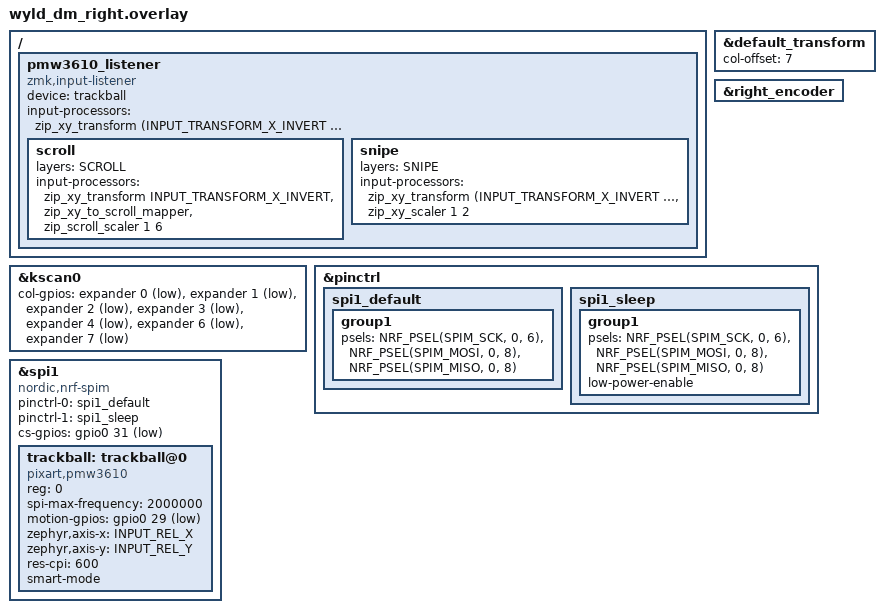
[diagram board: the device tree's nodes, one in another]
// wyld_dm_right.overlay

#define SCROLL 10
#define SNIPE  11

#include "wyld_dm.dtsi"
#include <dt-bindings/led/led.h>
#include <dt-bindings/input/input-event-codes.h>
#include <dt-bindings/zmk/input_transform.h>
#include <input/processors.dtsi>

&default_transform {
    col-offset = <7>;
};


///  NANO V2 PINS

&kscan0 {
    col-gpios
	= <&expander 0 (GPIO_ACTIVE_LOW | GPIO_PULL_UP)>
	, <&expander 1 (GPIO_ACTIVE_LOW | GPIO_PULL_UP)>
	, <&expander 2 (GPIO_ACTIVE_LOW | GPIO_PULL_UP)>
	, <&expander 3 (GPIO_ACTIVE_LOW | GPIO_PULL_UP)>
	, <&expander 4 (GPIO_ACTIVE_LOW | GPIO_PULL_UP)>
	, <&expander 6 (GPIO_ACTIVE_LOW | GPIO_PULL_UP)>
	, <&expander 7 (GPIO_ACTIVE_LOW | GPIO_PULL_UP)>

	;
};


&right_encoder {
	status = "okay";
};

&pinctrl {
    spi1_default: spi1_default {
        group1 {
            psels = <NRF_PSEL(SPIM_SCK, 0, 6)>,
                <NRF_PSEL(SPIM_MOSI, 0, 8)>,
                <NRF_PSEL(SPIM_MISO, 0, 8)>;
        };
    };
    spi1_sleep: spi1_sleep {
        group1 {
            psels = <NRF_PSEL(SPIM_SCK, 0, 6)>,
                <NRF_PSEL(SPIM_MOSI, 0, 8)>,
                <NRF_PSEL(SPIM_MISO, 0, 8)>;
            low-power-enable;
        };
    };
};

&spi1 {
  compatible = "nordic,nrf-spim";
  status = "okay";

  pinctrl-0 = <&spi1_default>;
  pinctrl-1 = <&spi1_sleep>;
  pinctrl-names = "default", "sleep";
  cs-gpios = <&gpio0 31 GPIO_ACTIVE_LOW>;
  trackball: trackball@0 {
      status = "okay";
      compatible = "pixart,pmw3610";
      reg = <0>;
      spi-max-frequency = <2000000>;
      motion-gpios = <&gpio0 29 (GPIO_ACTIVE_LOW | GPIO_PULL_UP)>;
      zephyr,axis-x = <INPUT_REL_X>;
      zephyr,axis-y = <INPUT_REL_Y>;
      res-cpi = <600>;
      smart-mode;
  };
};


/ {
  pmw3610_listener {
    compatible = "zmk,input-listener";
    device = <&trackball>;
    input-processors = <&zip_xy_transform (INPUT_TRANSFORM_X_INVERT | INPUT_TRANSFORM_Y_INVERT)>;

    scroll {
      layers = <SCROLL>;
      input-processors =
        <&zip_xy_transform INPUT_TRANSFORM_X_INVERT>,
        <&zip_xy_to_scroll_mapper>,
        <&zip_scroll_scaler 1 6>;
    };

    snipe {
      layers = <SNIPE>;
      input-processors =
        <&zip_xy_transform (INPUT_TRANSFORM_X_INVERT | INPUT_TRANSFORM_Y_INVERT)>,
        <&zip_xy_scaler 1 2>;
    };
  };
};
